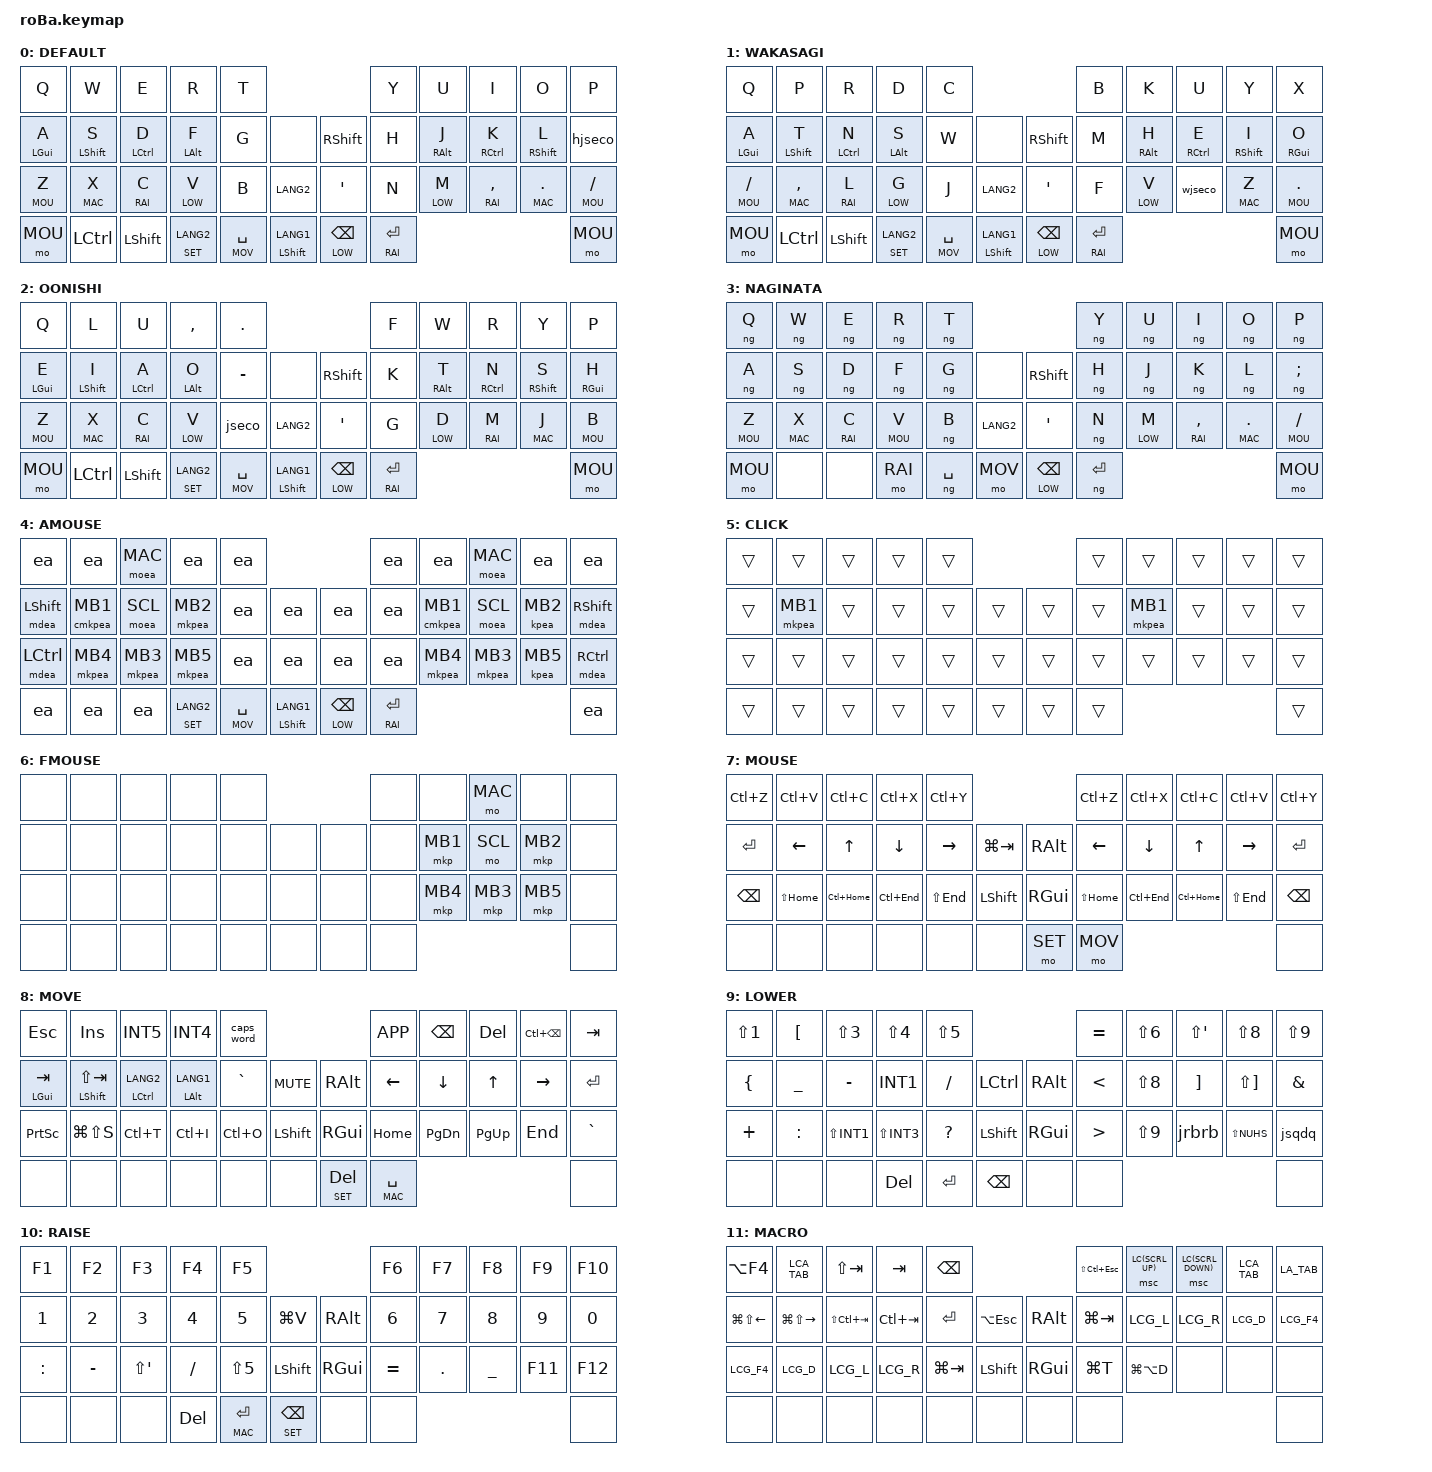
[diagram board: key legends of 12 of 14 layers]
#include <behaviors.dtsi>
#include <dt-bindings/zmk/bt.h>
#include <dt-bindings/zmk/keys.h>
#include <dt-bindings/zmk/pointing.h>
#include <input/processors.dtsi>
#include <dt-bindings/zmk/input_transform.h>
#include <behaviors/naginata.dtsi>

#define ZMK_POINTING_DEFAULT_MOVE_VAL 2200
#define ZMK_POINTING_DEFAULT_SCRL_VAL 100

// 薙刀式のOS設定  (WIN 0, MAC 1, LINUX 2, IOS 3)
#define HOST_OS 0

// レイヤー定義
#define QWE 0
#define WAK 1
#define ONI 2
#define NAG 3
#define AMO 4
#define CLI 5
#define FMO 6
#define MOU 7
#define MOV 8
#define LOW 9
#define RAI 10
#define MAC 11
#define SET 12
#define SCL 13

// keycodeを置き換えるとkeymap editorが利用できないため、基本的に実施しない。
//#define XXX &none
//#define ___ &none
// Misc aliases. [TODO: clean up]
//#define LG_S       &kp LG(S)             // スクリーンショット
//#define LA_F4      &kp LA(F4)            // アプリケーション終了
//#define LG_TAB     &kp LG(TAB)           // タスクビュー
//#define LCS_ESC    &kp LS(LC(ESC))       // タスクマネージャー
//#define LG_T       &kp LG(T)             // タスクバー選択
//#define LCS_TAB    &kp LS(LC(TAB))       // タブ移動(左)
//#define LC_TAB     &kp LC(TAB)           // タブ移動(右)
//#define LC_W       &kp LC(W)             // タブ削除
//#define LC_PLU     &kp LC(KP_PLUS)       // ズーム+
//#define LC_MIN     &kp LC(KP_MINUS)      // ズーム-
//#define LS_TAB     &kp LS(TAB)           // 入力移動（左）
//#define LS_HOME    &kp LS(HOME)          // カーソルから末尾まで選択
//#define LC_HOME    &kp LC(HOME)          // 先頭を表示
//#define LC_END     &kp LC(END)           // 最後尾を表示
//#define LS_END     &kp LS(END)           // カーソルから行頭まで選択
//#define LC_BS      &kp LC(BSPC)          // 単語削除
//#define LC_Z       &kp LC(Z)             // undo
//#define LC_V       &kp LC(V)             // paste
//#define LC_X       &kp LC(X)             // cut
//#define LC_C       &kp LC(C)             // copy
//#define LC_Y       &kp LC(Y)             // redo
//#define LC_T       &kp LC(T)             // 半角英数字
//#define LC_I       &kp LC(I)             // 全角カタカナ
//#define LC_O       &kp LC(O)             // 半角カタカナ

// layerの設定
&lt {
    flavor = "tap-preferred"; // タップ優先
    tapping-term-ms = <160>;  // tap < ms < hold 扱いになる
    quick-tap-ms = <160>;     // 秒数内にダブルタップすることで連続入力
    // require-prior-idle-ms = <125>;   // 修飾キー以外のキーと同時に押された場合（動作ではありません）、ホールドタップは常にタップに変換
};
&mt {
    flavor = "tap-preferred"; // タップ優先
    tapping-term-ms = <160>;  // tap < ms < hold 扱いになる
    quick-tap-ms = <160>;     // 秒数内にダブルタップすることで連続入力
    // require-prior-idle-ms = <125>;   // 修飾キー以外のキーと同時に押された場合（動作ではありません）、ホールドタップは常にタップに変換
};


// トラックボール
&trackball_listener{
    input-processors = <&zip_temp_layer AMO 10000>;  // オートマウスレイヤーを10秒間有効化
    snipe {     // マウス移動(LOW)
        layers = <MOV>;
        input-processors = <
            &zip_xy_scaler 1 3  // 移動量に倍率つける(0に近いほど小さくなる)
        >;
    };
    scroller {      //  スクロール
        layers = <SCL>;
        input-processors = <
            &zip_xy_to_scroll_mapper
            &zip_scroll_transform INPUT_TRANSFORM_Y_INVERT
            &zip_scroll_scaler 1 10
        >;
    };
    hiscroller {    // 高速スクロール
        layers = <MAC>;
        input-processors = <
            &zip_xy_to_scroll_mapper
            &zip_scroll_transform INPUT_TRANSFORM_Y_INVERT
            &zip_scroll_scaler 2 1
        >;
    }; 
    mouse {  // 固定マウス
       layers = <FMO>;
    };
};

/ {
    combos {
        compatible = "zmk,combos";
        // 薙刀式起動
        combo_ng_on {
            timeout-ms = <30>;
            key-positions = <17 18>;
            bindings = <&ng_on>;
            layers = <QWE>;
        };
        // 薙刀式終了
        combo_ng_off {
            timeout-ms = <30>;
            key-positions = <13 14>;
            bindings = <&ng_off>;
            layers = <QWE NAG>;
        };
        // wakasagi
        combo_wakasagi_on {
            timeout-ms = <30>;
            key-positions = <29 30>;
            bindings = <&to WAK>;
            layers = <QWE>;
        };
        // 大西式
        combo_oonishi_on {
            timeout-ms = <30>;
            key-positions = <30 31>;
            bindings = <&to ONI>;
            layers = <QWE>;
        };
        // デフォルトに戻す
        combo_qwerty_on {
            timeout-ms = <30>;
            key-positions = <24 25>;
            bindings = <&to QWE>;
            layers = <QWE WAK ONI>;
        };
        // マウスレイヤーに移動
        combo_fix_mouse_r_on {
            timeout-ms = <30>;
            key-positions = <6 7 8>;
            bindings = <&to FMO>;
            layers = <QWE WAK ONI>;
        };
        combo_fix_mouse_r_off {
            timeout-ms = <30>;
            key-positions = <30 31 32>;
            bindings = <&to QWE>;
            layers = <FMO>;
        };
        // ショートカット
        combo_LANG2 {
            timeout-ms = <30>;
            key-positions = <12 13>;
            bindings = <&kp LANG2>;
            layers = <QWE WAK ONI>;
        };
        combo_LANG1 {
            timeout-ms = <30>;
            key-positions = <18 19>;
            bindings = <&kp LANG1>;
            layers = <QWE WAK ONI>;
        };
        // ()
        combo_prn {
            timeout-ms = <40>;
            key-positions = <18 19>;
            bindings = <&JPRN2>;
            layers = <LOW>;
        };
        // []
        combo_brc {
            timeout-ms = <40>;
            key-positions = <19 20>;
            bindings = <&JBRC2>;
            layers = <LOW>;
        };
        // {}
        combo_cbr {
            timeout-ms = <40>;
            key-positions = <20 21>;
            bindings = <&JCBR2>;
            layers = <LOW>;
        };
        // <-
        combo_law {
            timeout-ms = <40>;
            key-positions = <30 31>;
            bindings = <&LAW>;
            layers = <LOW>;
        };
        // ->
        combo_raw {
            timeout-ms = <40>;
            key-positions = <31 32>;
            bindings = <&RAW>;
            layers = <LOW>;
        };
        combo_RAI {
            timeout-ms = <40>;
            key-positions = <32 33>;
            bindings = <&mo RAI>;
            layers = <QWE WAK ONI NAG>;
        };
        combo_RAI2 {
            timeout-ms = <40>;
            key-positions = <22 23>;
            bindings = <&mo RAI>;
            layers = <QWE WAK ONI NAG>;
        };
        combo_SET {
            timeout-ms = <40>;
            key-positions = <31 32>;
            bindings = <&mo SET>;
            layers = <QWE WAK ONI NAG>;
        };
        combo_SET2 {
            timeout-ms = <40>;
            key-positions = <23 24>;
            bindings = <&mo SET>;
            layers = <QWE WAK ONI NAG>;
        };
    };

    macros {
        // アクティブアプリ(切り替え)
        LA_TAB: alt_tab {
            compatible = "zmk,behavior-macro";
            #binding-cells = <0>;
            bindings = <&macro_press &kp LALT>,
                       <&macro_tap &kp TAB>,
                       <&macro_release &kp LALT>;
        };
        // アクティブアプリ(一覧)
        LCA_TAB: alt_ctrl_tab {
            compatible = "zmk,behavior-macro";
            #binding-cells = <0>;
            bindings = <&macro_press &kp LALT>,
                       <&macro_press &kp LCTRL>,
                       <&macro_wait_time 100>,
                       <&macro_tap &kp TAB>,
                       <&macro_release &kp LCTRL>,
                       <&macro_release &kp LALT>;
        };
        // 仮想デスクトップ 新規
        LCG_D: gui_ctrl_d {
            compatible = "zmk,behavior-macro";
            #binding-cells = <0>;
            bindings = <&macro_press &kp LGUI>,
                       <&macro_press &kp LCTRL>,
                       <&macro_tap &kp D>,
                       <&macro_release &kp LCTRL>,
                       <&macro_release &kp LGUI>;
        };
        // 仮想デスクトップ 削除
        LCG_F4: gui_ctrl_F4 {
            compatible = "zmk,behavior-macro";
            #binding-cells = <0>;
            bindings = <&macro_press &kp LGUI>,
                       <&macro_press &kp LCTRL>,
                       <&macro_tap &kp F4>,
                       <&macro_release &kp LCTRL>,
                       <&macro_release &kp LGUI>;
        };
        // 仮想デスクトップ 右移動
        LCG_R: gui_ctrl_right {
            compatible = "zmk,behavior-macro";
            #binding-cells = <0>;
            bindings = <&macro_press &kp LGUI>,
                       <&macro_press &kp LCTRL>,
                       <&macro_tap &kp RIGHT>,
                       <&macro_release &kp LCTRL>,
                       <&macro_release &kp LGUI>;
        };
        // 仮想デスクトップ 左移動
        LCG_L: gui_ctrl_left {
            compatible = "zmk,behavior-macro";
            #binding-cells = <0>;
            bindings = <&macro_press &kp LGUI>,
                       <&macro_press &kp LCTRL>,
                       <&macro_tap &kp LEFT>,
                       <&macro_release &kp LCTRL>,
                       <&macro_release &kp LGUI>;
        };
        // 括弧() JIS
        JPRN2: jis_lprn_rprn {
            compatible = "zmk,behavior-macro";
            #binding-cells = <0>;
            bindings = <&macro_tap &kp LS(N8)>,
                       <&macro_tap &kp LS(N9)>,
                       <&macro_tap &kp LEFT>;
        };
        // 括弧[] JIS
        JBRC2: jis_lbrc_rbrc {
            compatible = "zmk,behavior-macro";
            #binding-cells = <0>;
            bindings = <&macro_tap &kp RBKT>,
                       <&macro_tap &kp NUHS>,
                       <&macro_tap &kp LEFT>;
        };
        // 括弧{} JIS
        JCBR2: jis_lcbr_rcbr {
            compatible = "zmk,behavior-macro";
            #binding-cells = <0>;
            bindings = <&macro_tap &kp LS(RBKT)>,
                       <&macro_tap &kp LS(NUHS)>,
                       <&macro_tap &kp LEFT>;
        };
        // → JIS
        LAW: left_arrow {
            compatible = "zmk,behavior-macro";
            #binding-cells = <0>;
            bindings = <&macro_tap &kp LS(COMMA)>,
                       <&macro_tap &kp MINUS>;
        };
        // ← JIS
        RAW: right_arrow {
            compatible = "zmk,behavior-macro";
            #binding-cells = <0>;
            bindings = <&macro_tap &kp MINUS>,
                       <&macro_tap &kp LS(DOT)>;
        };
        // naginata
        ng_on: ng_on {
            compatible = "zmk,behavior-macro";
            #binding-cells = <0>;
            bindings
                = <&macro_tap &kp LANGUAGE_1 &kp INTERNATIONAL_4 &to NAG>
                ;
        };
        ng_off: ng_off {
            compatible = "zmk,behavior-macro";
            #binding-cells = <0>;
            bindings
                = <&macro_tap &kp LANGUAGE_2 &kp INTERNATIONAL_5 &to QWE>
                ;
        };
        // AMLを解除
        ea: exit_AML {
            compatible = "zmk,behavior-macro";
            wait-ms = <0>;
            tap-ms = <0>;
            #binding-cells = <0>;
            bindings = <&tog_off AMO>;
        };
        // マウスレイヤーでキー入力後抜ける
        kpea: kp_exit_AML {
            compatible = "zmk,behavior-macro-one-param";
            wait-ms = <0>;
            tap-ms = <0>;
            #binding-cells = <1>;
            bindings = <&macro_param_1to1 &kp MACRO_PLACEHOLDER &ea>;
        };
        // マウスレイヤーでmod入力後抜ける
        mdea: mod_exit_AML {
            compatible = "zmk,behavior-macro-one-param";
            wait-ms = <0>;
            tap-ms = <0>;
            #binding-cells = <1>;
            bindings =
                <&macro_press>,
                <&macro_param_1to1 &kp MACRO_PLACEHOLDER>,
                <&macro_pause_for_release>,
                <&macro_release>,
                <&macro_param_1to1 &kp MACRO_PLACEHOLDER>,
                <&macro_tap>,
                <&ea>;
        };
        // マウスレイヤーでmo入力後抜ける
        moea: mo_exit_AML {
            compatible = "zmk,behavior-macro-one-param";
            wait-ms = <0>;
            tap-ms = <0>;
            #binding-cells = <1>;
            bindings =
                <&macro_press>,
                <&macro_param_1to1 &mo MACRO_PLACEHOLDER>,
                <&macro_tap>,
                <&ea>,
                <&macro_pause_for_release>,
                <&macro_release>,
                <&macro_param_1to1 &mo MACRO_PLACEHOLDER>,
                <&macro_tap>;
        };
        // マウス入力
        cmkpea: mkp_exit_AML_click {
            compatible = "zmk,behavior-macro-one-param";
            #binding-cells = <1>;
            bindings =
                <&macro_press>,
                <&macro_param_1to1 &mkp MACRO_PLACEHOLDER>,
                <&macro_pause_for_release>,
                <&macro_release>,
                <&macro_param_1to1 &mkp MACRO_PLACEHOLDER>,
                <&macro_tap>,
                <&ea>,
                <&sl_150 CLI>;
        };
        // マウス入力
        mkpea: mkp_exit_AML {
            compatible = "zmk,behavior-macro-one-param";
            #binding-cells = <1>;
            bindings =
                <&macro_press>,
                <&macro_param_1to1 &mkp MACRO_PLACEHOLDER>,
                <&macro_pause_for_release>,
                <&macro_release>,
                <&macro_param_1to1 &mkp MACRO_PLACEHOLDER>,
                <&macro_tap>,
                <&ea>;
        };
    };

    behaviors {
        tog_on: toggle_layer_on {   // レイヤー有効化
            compatible = "zmk,behavior-toggle-layer";
            #binding-cells = <1>;
            display-name = "Toggle Layer On";
            toggle-mode = "on";
        };
        tog_off: toggle_layer_off {    // レイヤー無効化
            compatible = "zmk,behavior-toggle-layer";
            #binding-cells = <1>;
            display-name = "Toggle Layer Off";
            toggle-mode = "off";
        };
        sl_150: sl_150 {   // マウスレイヤーにとどまる時間
            compatible = "zmk,behavior-sticky-key";
            bindings = <&mo>;
            #binding-cells = <1>;
            release-after-ms = <150>;
        };
        // レイヤー移動後にAMLを抜ける
        ltea: lt_exit_AML {
            compatible = "zmk,behavior-hold-tap";
            bindings = <&moea>, <&kpea>;
            #binding-cells = <2>;
            tapping-term-ms = <180>;
            quick-tap-ms = <170>;
            flavor = "balanced";
        };
        // レイヤー移動後にAMLを抜ける
        mtea: mt_exit_AML {
            compatible = "zmk,behavior-hold-tap";
            bindings = <&moea>, <&kpea>;
            #binding-cells = <2>;
            tapping-term-ms = <180>;
            quick-tap-ms = <170>;
            flavor = "balanced";
        };
        // HRMの設定
        hrml: homerow_mods_left {
            compatible = "zmk,behavior-hold-tap";
            #binding-cells = <2>;
            require-prior-idle-ms = <150>;
            quick-tap-ms = <170>;
            tapping-term-ms = <200>;
            flavor = "balanced";
            bindings = <&kp>, <&kp>;
            hold-trigger-key-positions = <5 6 7 8 9 17 18 19 20 21 29 30 31 32 33 37 38 39 40 41>; // List of keys on the right side of the keyboard
            hold-trigger-on-release;
        };
        hrmr: homerow_mods_right {
            compatible = "zmk,behavior-hold-tap";
            #binding-cells = <2>;
            require-prior-idle-ms = <150>;
            quick-tap-ms = <170>;
            tapping-term-ms = <200>;
            flavor = "balanced";
            bindings = <&kp>, <&kp>;
            hold-trigger-key-positions = <0 1 2 3 4 10 11 12 13 14 22 23 24 25 26 37 38 39 40 41>;
            hold-trigger-on-release;
        };
        // HRMでcaps切替える
        hrmc: qickly_homerow_mods_caps {
            compatible = "zmk,behavior-hold-tap";
            #binding-cells = <2>;
            require-prior-idle-ms = <150>;
            quick-tap-ms = <170>;
            tapping-term-ms = <200>;
            flavor = "balanced";
            bindings = <&kp>, <&caps_word>;
            hold-trigger-key-positions = <5 6 7 8 9 17 18 19 20 21 29 30 31 32 33 37 38 39 40 41>;
            hold-trigger-on-release;
        };
        //mod-tap(薙刀式)の設定
        nltl: nagi_layer_tap_left {
            compatible = "zmk,behavior-hold-tap";
            #binding-cells = <2>;
            require-prior-idle-ms = <150>;
            tapping-term-ms = <200>;
            quick-tap-ms = <170>;
            flavor = "balanced";
            bindings = <&mo>, <&ng>;
            hold-trigger-key-positions = <5 6 7 8 9 17 18 19 20 21 29 30 31 32 33 37 38 39 40 41>;
            hold-trigger-on-release;
        };
        nltr: nagi_layer_tap_right {
            compatible = "zmk,behavior-hold-tap";
            #binding-cells = <2>;
            require-prior-idle-ms = <150>;
            tapping-term-ms = <200>;
            quick-tap-ms = <170>;
            flavor = "balanced";
            bindings = <&mo>, <&ng>;
            hold-trigger-key-positions = <0 1 2 3 4 10 11 12 13 14 22 23 24 25 26 37 38 39 40 41>;
            hold-trigger-on-release;
        };
        // layerの設定(文字を入力する場合)
        kltl: key_layer_tap_left {
            compatible = "zmk,behavior-hold-tap";
            #binding-cells = <2>;
            require-prior-idle-ms = <150>;
            tapping-term-ms = <200>;
            quick-tap-ms = <170>;
            flavor = "balanced";
            bindings = <&mo>, <&kp>;
            //hold-trigger-key-positions = <5 6 7 8 9 17 18 19 20 21 29 30 31 32 33 37 38 39 40 41>;
            //hold-trigger-on-release;
        };
        kltr: key_layer_tap_right {
            compatible = "zmk,behavior-hold-tap";
            #binding-cells = <2>;
            require-prior-idle-ms = <150>;
            tapping-term-ms = <200>;
            quick-tap-ms = <170>;
            flavor = "balanced";
            bindings = <&mo>, <&kp>;
            //hold-trigger-key-positions = <0 1 2 3 4 10 11 12 13 14 22 23 24 25 26 37 38 39 40 41>;
            //hold-trigger-on-release;
        }; 

        // ロータリーエンコーダの設定
        // スクロール動作の追加
        scroll_up_down: sensor_rotate_mouse_wheel_up_down {
            compatible = "zmk,behavior-sensor-rotate";
            #sensor-binding-cells = <0>;
            bindings = <&msc SCRL_UP>, <&msc SCRL_DOWN>;
            // 追加: スクロールのタップ時間を設定 (20ms)
            tap-ms = <20>;
        };
        scroll_left_right: sensor_rotate_mouse_wheel_left_right {
            compatible = "zmk,behavior-sensor-rotate";
            #sensor-binding-cells = <0>;
            bindings = <&msc SCRL_LEFT>, <&msc SCRL_RIGHT>;
            // 追加: スクロールのタップ時間を設定 (20ms)
            tap-ms = <20>;
        };
        // 仮想デスクトップ移動
        move_vdesktop_lr: sensor_rotate_move_vdesktop_left_right  {
            compatible = "zmk,behavior-sensor-rotate";
            #sensor-binding-cells = <0>;
            bindings = <&LCG_R>, <&LCG_L>;
            // 追加: スクロールのタップ時間を設定 (20ms)
            tap-ms = <20>;
        };
        // 音量増減
        volume_up_down: sensor_rotate_volume_up_down  {
            compatible = "zmk,behavior-sensor-rotate";
            #sensor-binding-cells = <0>;
            bindings = <&kp C_VOL_UP>, <&kp C_VOL_DN>;
            // 追加: スクロールのタップ時間を設定 (20ms)
            tap-ms = <20>;
        };
        // タブ移動
        move_tab_lr: sensor_rotate_move_tab_left_right  {
            compatible = "zmk,behavior-sensor-rotate";
            #sensor-binding-cells = <0>;
            bindings = <&kp LC(TAB)>, <&kp LS(LC(TAB))>;
            // 追加: スクロールのタップ時間を設定 (20ms)
            tap-ms = <20>;
        };
        // 進む/戻る
        move_reun: sensor_rotate_move_redo_undo  {
            compatible = "zmk,behavior-sensor-rotate";
            #sensor-binding-cells = <0>;
            bindings = <&kp LC(Y)>, <&kp LC(Z)>;
            // 追加: スクロールのタップ時間を設定 (20ms)
            tap-ms = <20>;
        };
        // 右/左
        move_leri: sensor_rotate_move_left_right  {
            compatible = "zmk,behavior-sensor-rotate";
            #sensor-binding-cells = <0>;
            bindings = <&kp RIGHT>, <&kp LEFT>;
            // 追加: スクロールのタップ時間を設定 (20ms)
            tap-ms = <20>;
        };
        // キー入力受付
         rot_kp: sensor_rotate_kp {
            compatible = "zmk,behavior-sensor-rotate-var";
            #sensor-binding-cells = <2>;
            bindings = <&kp>, <&kp>;
            tap-ms = <1>;
        };

        // HRMで記号の入力を指定
        hjseco: homerow_mods_jis_semi_colon {
            compatible = "zmk,behavior-mod-morph";
            #binding-cells = <0>;
            bindings = <&hrmr RGUI SEMI>, <&kp SQT>;
            mods = <(MOD_LSFT|MOD_RSFT)>;
        };
        wjseco: wakasagi_jis_semi_colon {
            compatible = "zmk,behavior-mod-morph";
            #binding-cells = <0>;
            bindings = <&kltr RAI SEMI>, <&kp SQT>;
            mods = <(MOD_LSFT|MOD_RSFT)>;
        };
        // 記号の入力
        jseco: jis_semi_colon {
            compatible = "zmk,behavior-mod-morph";
            #binding-cells = <0>;
            bindings = <&kp SEMI>, <&kp SQT>;
            mods = <(MOD_LSFT|MOD_RSFT)>;
        };
        // 記号の入力
        jsqdq: jis_sqt_dqt {
            compatible = "zmk,behavior-mod-morph";
            #binding-cells = <0>;
            bindings = <&kp AT>, <&kp AMPS>;
            mods = <(MOD_LSFT|MOD_RSFT)>;
        };
        // 記号の入力
        jrbrb: jis_rbkt_rbrc {
            compatible = "zmk,behavior-mod-morph";
            #binding-cells = <0>;
            bindings = <&kp NUHS>, <&kp LS(NUHS)>;
            mods = <(MOD_LSFT|MOD_RSFT)>;
        };
    };

    keymap {
        compatible = "zmk,keymap";

        /*
        map = <
            RC(0,0) RC(0,1) RC(0,2) RC(0,3) RC(0,4)                     RC(0,6) RC(0,7) RC(0,8) RC(0,9) RC(0,10)
            RC(1,0) RC(1,1) RC(1,2) RC(1,3) RC(1,4) RC(1,5)     RC(3,6) RC(1,6) RC(1,7) RC(1,8) RC(1,9) RC(1,10)
            RC(2,0) RC(2,1) RC(2,2) RC(2,3) RC(2,4) RC(2,5)     RC(3,7) RC(2,6) RC(2,7) RC(2,8) RC(2,9) RC(2,10)
            RC(3,0) RC(3,1) RC(3,2) RC(3,3) RC(3,4) RC(3,5)     RC(3,8) RC(3,9)                         RC(3,10)
        >;

        number
            00  01  02  03  04                  05  06  07  08  09
            10  11  12  13  14  15          16  17  18  19  20  21
            22  23  24  25  26  27          28  29  30  31  32  33
            34  35  36  37  38  39          40  41              42
        */

        DEFAULT {
            bindings = <
&kp Q         &kp W          &kp E          &kp R         &kp T                                              &kp Y        &kp U         &kp I            &kp O          &kp P
&hrml LGUI A  &hrml LSHFT S  &hrml LCTRL D  &hrml LALT F  &kp G          &none                 &kp RSHFT     &kp H        &hrmr RALT J  &hrmr RCTRL K    &hrmr RSHFT L  &hjseco
&kltl MOU Z   &kltl MAC X    &kltl RAI C    &kltl LOW V   &kp B          &kp LANG2             &kp SQT       &kp N        &kltr LOW M   &kltr RAI COMMA  &kltr MAC DOT  &kltr MOU FSLH
&mo MOU       &kp LCTRL      &kp LSHFT      &lt SET LANG2 &lt MOV SPACE  &mt LSHFT LANG1       &lt LOW BSPC  &lt RAI RET                                                &mo MOU
            >;
            sensor-bindings = <&scroll_up_down>;
        };

        WAKASAGI {
            bindings = <
&kp Q           &kp P            &kp R          &kp D          &kp C                                            &kp B        &kp K         &kp U          &kp Y          &kp X
&hrml LGUI A    &hrml LSHFT T    &hrml LCTRL N  &hrml LALT S   &kp W          &none               &kp RSHFT     &kp M        &hrmr RALT H  &hrmr RCTRL E  &hrmr RSHFT I  &hrmr RGUI O
&kltl MOU FSLH  &kltl MAC COMMA  &kltl RAI L    &kltl LOW G    &kp J          &kp LANG2           &kp SQT       &kp F        &kltr LOW V   &wjseco        &kltr MAC Z    &kltr MOU DOT
&mo MOU         &kp LCTRL        &kp LSHFT      &lt SET LANG2  &lt MOV SPACE  &mt LSHFT LANG1     &lt LOW BSPC  &lt RAI RET                                              &mo MOU
            >;
            sensor-bindings = <&scroll_up_down>;
        };

        OONISHI {
            bindings = <
&kp Q         &kp L          &kp U          &kp COMMA      &kp DOT                                            &kp F        &kp W         &kp R          &kp Y          &kp P
&hrml LGUI E  &hrml LSHFT I  &hrml LCTRL A  &hrml LALT O   &kp MINUS      &none                 &kp RSHFT     &kp K        &hrmr RALT T  &hrmr RCTRL N  &hrmr RSHFT S  &hrmr RGUI H
&kltl MOU Z   &kltl MAC X    &kltl RAI C    &kltl LOW V    &jseco         &kp LANG2             &kp SQT       &kp G        &kltr LOW D   &kltr RAI M    &kltr MAC J    &kltr MOU B
&mo MOU       &kp LCTRL      &kp LSHFT      &lt SET LANG2  &lt MOV SPACE  &mt LSHFT LANG1       &lt LOW BSPC  &lt RAI RET                                              &mo MOU
            >;
            sensor-bindings = <&scroll_up_down>;
        };

        NAGINATA {
            bindings = <
&ng Q        &ng W        &ng E        &ng R        &ng T                                     &ng Y      &ng U        &ng I            &ng O          &ng P
&ng A        &ng S        &ng D        &ng F        &ng G      &none            &kp RSHFT     &ng H      &ng J        &ng K            &ng L          &ng SEMI
&nltl MOU Z  &nltl MAC X  &nltl RAI C  &nltl MOU V  &ng B      &kp LANG2        &kp SQT       &ng N      &nltr LOW M  &nltr RAI COMMA  &nltr MAC DOT  &nltr MOU FSLH
&mo MOU      &none        &none        &mo RAI      &ng SPACE  &mo MOV          &lt LOW BSPC  &ng ENTER                                               &mo MOU
            >;
            sensor-bindings = <&scroll_up_down>;
        };

        AMOUSE {
             bindings = < 
&ea          &ea          &moea MAC   &ea              &ea                                                    &ea            &ea          &moea MAC   &ea        &ea
&mdea LSHFT  &cmkpea MB1  &moea SCL   &mkpea MB2       &ea              &ea                   &ea             &ea            &cmkpea MB1  &moea SCL   &kpea MB2  &mdea RSHFT
&mdea LCTRL  &mkpea MB4   &mkpea MB3  &mkpea MB5       &ea              &ea                   &ea             &ea            &mkpea MB4   &mkpea MB3  &kpea MB5  &mdea RCTRL
&ea          &ea          &ea         &ltea SET LANG2  &ltea MOV SPACE  &mtea LSHFT LANG1     &ltea LOW BSPC  &ltea RAI RET                                      &ea
            >;
            sensor-bindings = <&scroll_up_down>;
        };

        CLICK {
            bindings = <
&trans  &trans      &trans  &trans  &trans                     &trans  &trans      &trans  &trans  &trans
&trans  &mkpea MB1  &trans  &trans  &trans  &trans     &trans  &trans  &mkpea MB1  &trans  &trans  &trans
&trans  &trans      &trans  &trans  &trans  &trans     &trans  &trans  &trans      &trans  &trans  &trans
&trans  &trans      &trans  &trans  &trans  &trans     &trans  &trans                              &trans
            >;
            sensor-bindings = <&scroll_up_down>;
        };

        FMOUSE {
            bindings = <
&none  &none  &none  &none  &none                   &none  &none     &mo MAC   &none     &none
&none  &none  &none  &none  &none  &none     &none  &none  &mkp MB1  &mo SCL   &mkp MB2  &none
&none  &none  &none  &none  &none  &none     &none  &none  &mkp MB4  &mkp MB3  &mkp MB5  &none
&none  &none  &none  &none  &none  &none     &none  &none                                &none
            >;
            sensor-bindings = <&scroll_up_down>;
        };

        MOUSE {
            bindings = <
&kp LC(Z)  &kp LC(V)     &kp LC(C)     &kp LC(X)    &kp LC(Y)                              &kp LC(Z)     &kp LC(X)    &kp LC(C)     &kp LC(V)    &kp LC(Y)
&kp RET    &kp LEFT      &kp UP        &kp DOWN     &kp RIGHT    &kp LG(TAB)     &kp RALT  &kp LEFT      &kp DOWN     &kp UP        &kp RIGHT    &kp RET
&kp BSPC   &kp LS(HOME)  &kp LC(HOME)  &kp LC(END)  &kp LS(END)  &kp LSHFT       &kp RGUI  &kp LS(HOME)  &kp LC(END)  &kp LC(HOME)  &kp LS(END)  &kp BSPC
&none      &none         &none         &none        &none        &none           &mo SET   &mo MOV                                               &none
            >;
            sensor-bindings = <&move_vdesktop_lr>;
        };

        MOVE {
            bindings = <
&kp ESC         &kp INS              &kp INT5           &kp INT4          &caps_word                              &kp K_APP      &kp BSPC   &kp DEL    &kp LC(BSPC)  &kp TAB
&hrml LGUI TAB  &hrml LSHFT LS(TAB)  &hrml LCTRL LANG2  &hrml LALT LANG1  &kp GRAVE   &kp C_MUTE     &kp RALT     &kp LEFT       &kp DOWN   &kp UP     &kp RIGHT     &kp RET
&kp PSCRN       &kp LG(LS(S))        &kp LC(T)          &kp LC(I)         &kp LC(O)   &kp LSHFT      &kp RGUI     &kp HOME       &kp PG_DN  &kp PG_UP  &kp END       &kp GRAVE
&none           &none                &none              &none             &none       &none          &lt SET DEL  &lt MAC SPACE                                      &none
            >;
            sensor-bindings = <&volume_up_down>;
        };

        LOWER {
            bindings = <
&kp LS(N1)  &kp LBKT   &kp LS(N3)    &kp LS(N4)    &kp LS(N5)                          &kp EQUAL  &kp LS(N6)  &kp LS(SQT)  &kp LS(N8)    &kp LS(N9)
&kp LBRC    &kp UNDER  &kp MINUS     &kp INT1      &kp FSLH    &kp LCTRL     &kp RALT  &kp LT     &kp LS(N8)  &kp RBKT     &kp LS(RBKT)  &kp AMPS
&kp PLUS    &kp COLON  &kp LS(INT1)  &kp LS(INT3)  &kp QMARK   &kp LSHFT     &kp RGUI  &kp GT     &kp LS(N9)  &jrbrb       &kp LS(NUHS)  &jsqdq
&none       &none      &none         &kp DEL       &kp RET     &kp BSPC      &none     &none                                             &none
            >;
            sensor-bindings = <&rot_kp  LC(TAB) LS(LC(TAB))>;
        };

        RAISE {
            bindings = <
&kp F1     &kp F2     &kp F3       &kp F4    &kp F5                                  &kp F6     &kp F7   &kp F8     &kp F9   &kp F10
&kp N1     &kp N2     &kp N3       &kp N4    &kp N5       &kp LG(V)        &kp RALT  &kp N6     &kp N7   &kp N8     &kp N9   &kp N0
&kp COLON  &kp MINUS  &kp LS(SQT)  &kp FSLH  &kp LS(N5)   &kp LSHFT        &kp RGUI  &kp EQUAL  &kp DOT  &kp UNDER  &kp F11  &kp F12
&none      &none      &none        &kp DEL   &lt MAC RET  &lt SET BSPC     &none     &none                                   &none
            >;
            sensor-bindings = <&move_reun>;
        };

        MACRO {
            bindings = <
&kp LA(F4)        &LCA_TAB           &kp LS(TAB)      &kp TAB        &kp BSPC                           &kp LS(LC(ESC))  &msc LC(SCRL_UP)  &msc LC(SCRL_DOWN)  &LCA_TAB    &LA_TAB
&kp LG(LS(LEFT))  &kp LG(LS(RIGHT))  &kp LS(LC(TAB))  &kp LC(TAB)    &kp RET     &kp LA(ESC)  &kp RALT  &kp LG(TAB)      &LCG_L            &LCG_R              &LCG_D      &LCG_F4
&LCG_F4           &LCG_D             &LCG_L           &LCG_R         &kp LG(TAB) &kp LSHFT    &kp RGUI  &kp LG(T)        &kp LG(LA(D))     &none               &none       &none
&none             &none              &none            &none          &none       &none        &none     &none                                                              &none
            >;
            sensor-bindings = <&move_leri>;
        };

        SETUP {
            bindings = <
&kp C_MUTE    &kp C_PP    &none         &none  &kp LCAPS                               &kp CAPS    &none  &bt BT_SEL 0  &bt BT_SEL 1  &bt BT_SEL 2
&kp C_VOL_UP  &kp C_NEXT  &kp C_BRI_UP  &none  &kp LNLCK  &none           &none        &kp KP_NUM  &none  &bt BT_SEL 3  &bt BT_SEL 4  &bt BT_SEL 5
&kp C_VOL_DN  &kp C_PREV  &kp C_BRI_DN  &none  &kp LSLCK  &bootloader     &bootloader  &kp SLCK    &none  &none         &bt BT_CLR    &bt BT_CLR_ALL
&sys_reset    &none       &none         &none  &none      &none           &none        &none                                          &sys_reset
            >;
            sensor-bindings = <&scroll_up_down>;
        };

        SCROLL {
            bindings = <
&none  &none  &none  &none  &none                   &none  &none  &none  &none  &none
&none  &none  &none  &none  &none  &none     &none  &none  &none  &none  &none  &none
&none  &none  &none  &none  &none  &none     &none  &none  &none  &none  &none  &none
&none  &none  &none  &none  &none  &none     &none  &none                       &none
            >;
            sensor-bindings = <&scroll_up_down>;
        };
    };
};
